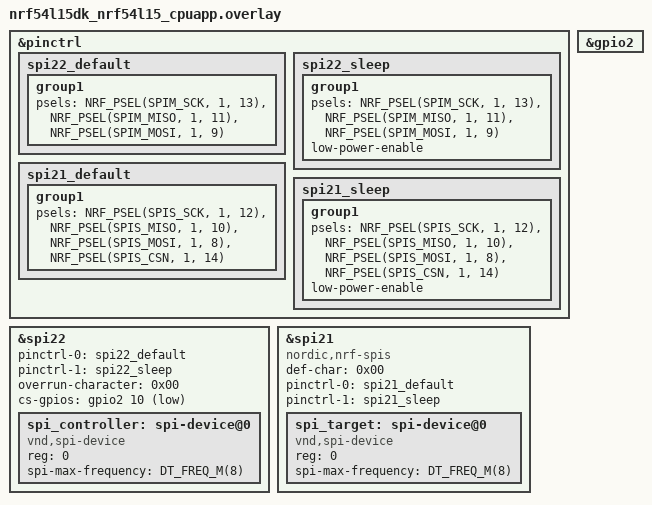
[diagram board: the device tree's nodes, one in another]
/*
 * SPDX-FileCopyrightText: Copyright 2026 Nordic Semiconductor ASA
 *
 * SPDX-License-Identifier: Apache-2.0
 */

/*
 * SCK = P1.12 and P1.13
 * MISO = P1.10 and P1.11
 * MOSI = P1.08 and P1.09
 * CSN = P1.14 and P2.10
 */

&pinctrl {
	spi22_default: spi22_default {
		group1 {
			psels = <NRF_PSEL(SPIM_SCK, 1, 13)>,
				<NRF_PSEL(SPIM_MISO, 1, 11)>,
				<NRF_PSEL(SPIM_MOSI, 1, 9)>;
		};
	};

	spi22_sleep: spi22_sleep {
		group1 {
			psels = <NRF_PSEL(SPIM_SCK, 1, 13)>,
				<NRF_PSEL(SPIM_MISO, 1, 11)>,
				<NRF_PSEL(SPIM_MOSI, 1, 9)>;
			low-power-enable;
		};
	};

	spi21_default: spi21_default {
		group1 {
			psels = <NRF_PSEL(SPIS_SCK, 1, 12)>,
				<NRF_PSEL(SPIS_MISO, 1, 10)>,
				<NRF_PSEL(SPIS_MOSI, 1, 8)>,
				<NRF_PSEL(SPIS_CSN, 1, 14)>;
		};
	};

	spi21_sleep: spi21_sleep {
		group1 {
			psels = <NRF_PSEL(SPIS_SCK, 1, 12)>,
				<NRF_PSEL(SPIS_MISO, 1, 10)>,
				<NRF_PSEL(SPIS_MOSI, 1, 8)>,
				<NRF_PSEL(SPIS_CSN, 1, 14)>;
			low-power-enable;
		};
	};
};

&gpio2 {
	status = "okay";
};

&spi22 {
	status = "okay";
	pinctrl-0 = <&spi22_default>;
	pinctrl-1 = <&spi22_sleep>;
	pinctrl-names = "default", "sleep";
	overrun-character = <0x00>;
	cs-gpios = <&gpio2 10 GPIO_ACTIVE_LOW>;

	spi_controller: spi-device@0 {
		compatible = "vnd,spi-device";
		reg = <0>;
		spi-max-frequency = <DT_FREQ_M(8)>;
	};
};

&spi21 {
	compatible = "nordic,nrf-spis";
	status = "okay";
	def-char = <0x00>;
	pinctrl-0 = <&spi21_default>;
	pinctrl-1 = <&spi21_sleep>;
	pinctrl-names = "default", "sleep";
	/delete-property/ rx-delay-supported;
	/delete-property/ rx-delay;

	spi_target: spi-device@0 {
		compatible = "vnd,spi-device";
		reg = <0>;
		spi-max-frequency = <DT_FREQ_M(8)>;
	};
};
